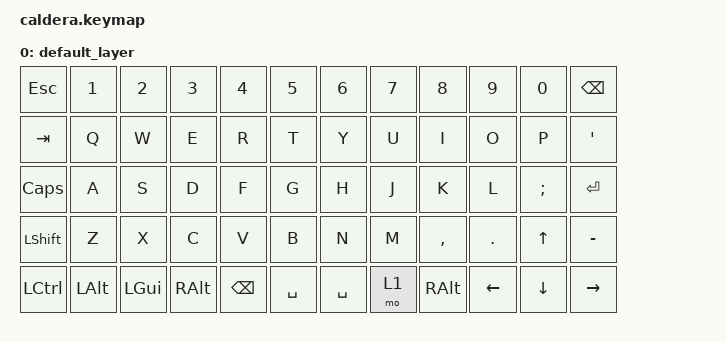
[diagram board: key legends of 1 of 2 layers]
#include <behaviors.dtsi>
#include <dt-bindings/zmk/bt.h>
#include <dt-bindings/zmk/keys.h>

/ {
    keymap {
        compatible = "zmk,keymap";

        default_layer {
            // ---------------------------------------------------------------------------------
            // |  ESC |  1  |  2  |  3  |  4  |  5  |     |  6  |  7  |  8  |  9  |  0  | BKSP |
            // |  TAB |  Q  |  W  |  E  |  R  |  T  |     |  Y  |  U  |  I  |  O  |  P  |  \   |
            // | CAPS |  A  |  S  |  D  |  F  |  G  |     |  H  |  J  |  K  |  L  |  ;  |  ENT |
            // | SHFT |  Z  |  X  |  C  |  V  |  B  |     |  N  |  M  |  ,  |  .  |  /  | APOS |
            // | CTRL | ALT | GUI | SPC | SPC | SPC |     | SPC | LOW |LARW |DARW |UARW | RARW |

            bindings = <
&kp ESC    &kp N1    &kp N2    &kp N3         &kp N4         &kp N5       &kp N6     &kp N7  &kp N8         &kp N9          &kp N0          &kp BSPC
&kp TAB    &kp Q     &kp W     &kp E          &kp R          &kp T        &kp Y      &kp U   &kp I          &kp O           &kp P           &kp APOSTROPHE
&kp CAPS   &kp A     &kp S     &kp D          &kp F          &kp G        &kp H      &kp J   &kp K          &kp L           &kp SEMI        &kp RET
&kp LSHFT  &kp Z     &kp X     &kp C          &kp V          &kp B        &kp N      &kp M   &kp COMMA      &kp DOT         &kp UP_ARROW    &kp MINUS
&kp LCTRL  &kp LALT  &kp LGUI  &kp RIGHT_ALT  &kp BACKSPACE  &kp SPACE    &kp SPACE  &mo 1   &kp RIGHT_ALT  &kp LEFT_ARROW  &kp DOWN_ARROW  &kp RIGHT_ARROW
            >;
        };

        lower_layer {
            // ------------------------------------------------------------------------------------------------------------
            // |   F1  |   F2  |   F3  |   F4  |   F5  |    F6 |          |    F7   |    F8    |    F9   |   F10   |   F11    |  F12  |
            // |       |       |       |       |       |       |          |         |          |         |         |          |       |
            // |       |       |       | LPAR  | RPAR  |       |          |         |   LBKT   |   RBKT  |         |          |       |
            // |       |   <   |   >   |       |       |       |          |         |          |         |         |          |       |

            bindings = <
&kp F1          &kp F2          &kp F3        &kp F4         &kp F5         &kp F6              &kp F7            &kp F8             &kp F9                &kp F10                &kp F11       &kp F12
&kp LANGUAGE_1  &kp LANGUAGE_2  &kp ASTERISK  &kp AMPERSAND  &kp LESS_THAN  &kp GREATER_THAN    &kp LEFT_BRACE    &kp RIGHT_BRACE    &kp LEFT_PARENTHESIS  &kp RIGHT_PARENTHESIS  &kp EXCL      &kp QUESTION
&trans          &trans          &trans        &kp PIPE       &kp MINUS      &kp PLUS            &kp LEFT_BRACKET  &kp RIGHT_BRACKET  &trans                &trans                 &bt BT_CLR    &bt BT_CLR_ALL
&trans          &trans          &trans        &trans         &trans         &kp EQUAL           &kp SLASH         &kp BACKSLASH      &bt BT_SEL 0          &bt BT_SEL 1           &bt BT_SEL 3  &bt BT_SEL 4
            >;
        };
    };
};
